# LPC408x_7x register map
File version: 0.6
CPU: CM4 r0p0, little endian, no MPU, no FPU, 3 interrupt priority bits
Registers are 32-bit, read-write, reset 0x0 unless marked. A register's access mark holds for its fields unless they carry their own. Offsets are from the block's base; [hi:lo] are bit positions; {n}, {i} and the like mark numbered series.

## GPIO
Base 0x20098000
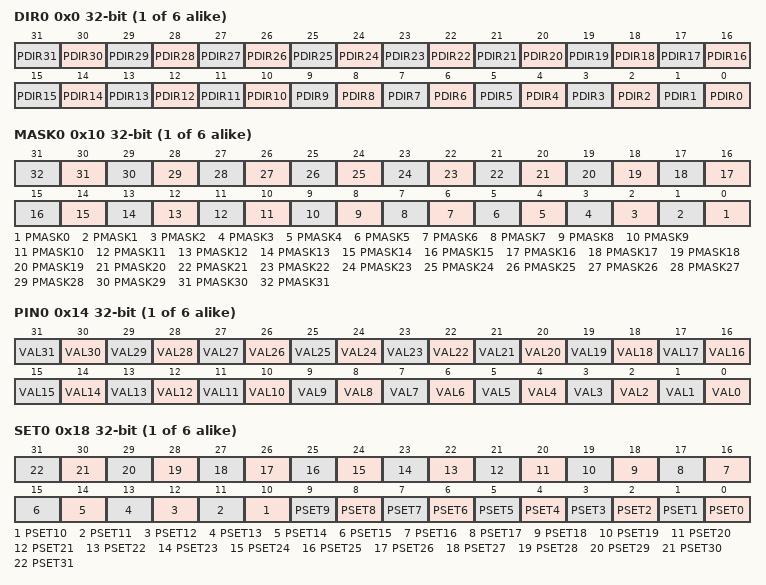
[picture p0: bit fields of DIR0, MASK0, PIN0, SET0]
{0x0+0x20*i} DIR{i} (i=0..5) — GPIO Port Direction control register.
  [n] PDIR{n} (n=0..31) — Fast GPIO Direction PORTx control bits. Bit 0 in xDIR controls pin Px[0], bit 31 in xDIR controls pin Px[31]. 0 = Controlled pin is input. 1 = Controlled pin is output.
{0x10+0x20*i} MASK{i} (i=0..5) — Mask register for Port.
  [n] PMASK{n} (n=0..31) — Fast GPIO physical pin access control. 0 = Controlled pin is affected by writes to the port's xSET, xCLR, and xPIN register(s). Current state of the pin can be read from the xPIN register. 1 = Controlled pin is not affected by writes into the port's xSET, xCLR and xPIN register(s). When the xPIN register is read, this bit will not be updated with the state of the physical pin.
{0x14+0x20*i} PIN{i} (i=0..5) — Port Pin value register using MASK.
  [n] VAL{n} (n=0..31) — Fast GPIO output value Set bits. Bit 0 in xCLR corresponds to pin Px[0], bit 31 in xCLR corresponds to pin Px[31]. 0 = Controlled pin output is set to LOW. 1 = Controlled pin output is set to HIGH.
{0x18+0x20*i} SET{i} (i=0..5) — Port Output Set register using MASK.
  [n] PSET{n} (n=0..31) — Fast GPIO output value Set bits. Bit 0 in xSET controls pin Px[0], bit 31 in xSET controls pin Px[31]. 0 = Controlled pin output is unchanged. 1 = Controlled pin output is set to HIGH.
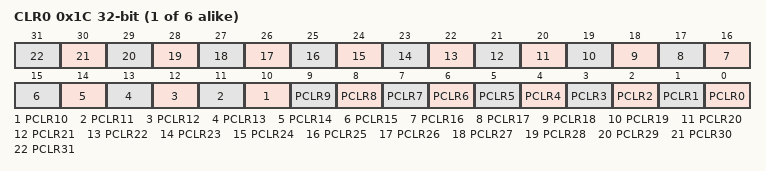
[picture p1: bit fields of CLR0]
{0x1C+0x20*i} CLR{i} (i=0..5) wo — Port Output Clear register using MASK.
  [n] PCLR{n} (n=0..31) — Fast GPIO output value Clear bits. Bit 0 in xCLR controls pin Px[0], bit 31 controls pin Px[31]. 0 = Controlled pin output is unchanged. 1 = Controlled pin output is set to LOW.

## WWDT — Windowed Watchdog Timer (WWDT)
Base 0x40000000
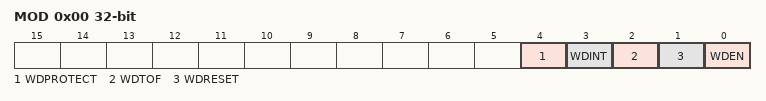
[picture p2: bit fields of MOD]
0x00 MOD — Watchdog mode register. This register determines the basic mode and status of the Watchdog Timer.
  [4] WDPROTECT — Watchdog update mode. This bit is Set Only. See Section WDPROTECT.
    0=CHANGE (The watchdog reload value (WDTC) can be changed at any time.); 1=CHANGE_W_CNT (The watchdog reload value (WDTC) can be changed only after the counter is below the value of WDWARNINT and WDWINDOW. Note: this mode is intended for use only when WDRESET =1.)
  [3] WDINT — Watchdog interrupt flag. Set when the timer reaches the value in WDWARNINT. Cleared by software. See Section WDINT.
  [2] WDTOF — Watchdog time-out flag. Set when the watchdog timer times out, by a feed error, or by events associated with WDPROTECT, cleared by software. Causes a chip reset if WDRESET = 1. See Section WDTOF.
  [1] WDRESET — Watchdog reset enable bit. This bit is Set Only. See Table 652.
    0=NORESET (A watchdog timeout will not cause a chip reset.); 1=RESET (A watchdog timeout will cause a chip reset.)
  [0] WDEN — Watchdog enable bit. This bit is Set Only. See Table 652.
    0=STOP (The watchdog timer is stopped.); 1=RUN (The watchdog timer is running.)
0x04 TC reset 0xFF — Watchdog timer constant register. The value in this register determines the time-out value.
  [23:0] Count — Watchdog time-out interval.
0x08 FEED wo reset not defined — Watchdog feed sequence register. Writing 0xAA followed by 0x55 to this register reloads the Watchdog timer with the value contained in WDTC.
  [7:0] Feed — Feed value should be 0xAA followed by 0x55.
0x0C TV ro reset 0xFF — Watchdog timer value register. This register reads out the current value of the Watchdog timer.
  [23:0] Count — Counter timer value.
0x14 WARNINT — Watchdog Warning Interrupt compare value.
  [9:0] WARNINT — Watchdog warning interrupt compare value.
0x18 WINDOW reset 0xFFFFFF — Watchdog Window compare value.
  [23:0] WINDOW — Watchdog window value.

## GPIOINT — GPIO
Base 0x40028080
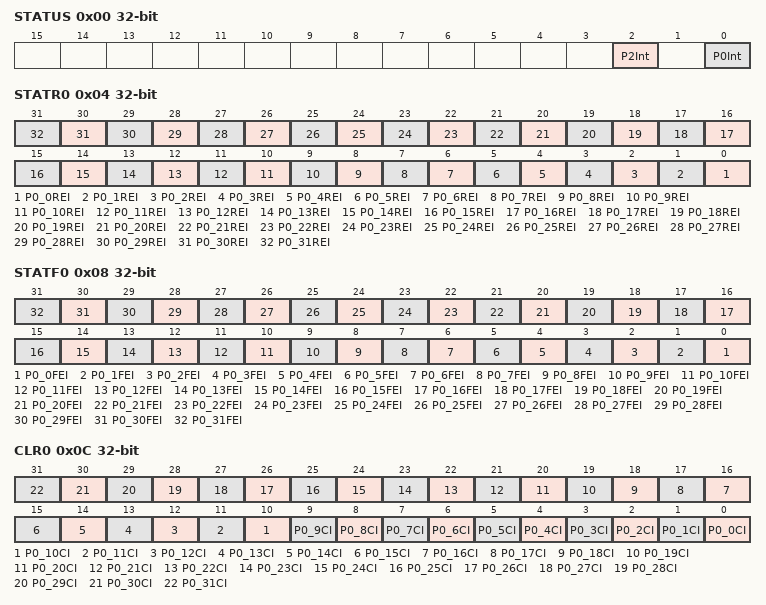
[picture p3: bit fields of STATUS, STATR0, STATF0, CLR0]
0x00 STATUS ro — GPIO overall Interrupt Status.
  [2] P2Int — Port 2 GPIO interrupt pending.
    0=NO_PENDING_INTERRUPT (No pending interrupts on Port 2.); 1=AT_LEAST_ONE_PENDING (At least one pending interrupt on Port 2.)
  [0] P0Int — Port 0 GPIO interrupt pending.
    0=NO_PENDING_INTERRUPT (No pending interrupts on Port 0.); 1=AT_LEAST_ONE_PENDING (At least one pending interrupt on Port 0.)
0x04 STATR0 ro — GPIO Interrupt Status for Rising edge for Port 0.
  [n] P0_{n}REI (n=0..31) — Status of Rising Edge Interrupt for P0[{n}]. 0 = No rising edge detected. 1 = Rising edge interrupt generated.
0x08 STATF0 ro — GPIO Interrupt Status for Falling edge for Port 0.
  [n] P0_{n}FEI (n=0..31) — Status of Falling Edge Interrupt for P0[{n}]. 0 = No falling edge detected. 1 = Falling edge interrupt generated.
0x0C CLR0 wo — GPIO Interrupt Clear.
  [n] P0_{n}CI (n=0..31) — Clear GPIO port Interrupts for P0[{n}]. 0 = No effect. 1 = Clear corresponding bits in IOnINTSTATR and IOnSTATF.
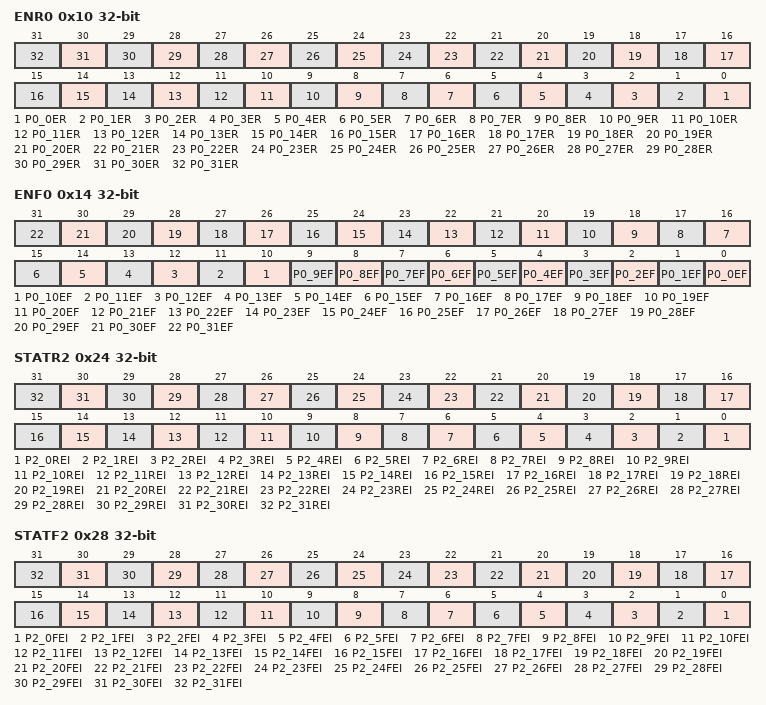
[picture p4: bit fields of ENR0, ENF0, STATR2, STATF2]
0x10 ENR0 — GPIO Interrupt Enable for Rising edge for Port 0.
  [n] P0_{n}ER (n=0..31) — Enable rising edge interrupt for P0[{n}]. 0 = Disable rising edge interrupt. 1 = Enable rising edge interrupt.
0x14 ENF0 — GPIO Interrupt Enable for Falling edge for Port 0.
  [n] P0_{n}EF (n=0..31) — Enable falling edge interrupt for P0[{n}]. 0 = Disable falling edge interrupt. 1 = Enable falling edge interrupt.
0x24 STATR2 ro — GPIO Interrupt Status for Rising edge for Port 0.
  [n] P2_{n}REI (n=0..31) — Status of Rising Edge Interrupt for P2[{n}]. 0 = No rising edge detected. 1 = Rising edge interrupt generated.
0x28 STATF2 ro — GPIO Interrupt Status for Falling edge for Port 0.
  [n] P2_{n}FEI (n=0..31) — Status of Falling Edge Interrupt for P2[{n}]. 0 = No falling edge detected. 1 = Falling edge interrupt generated.
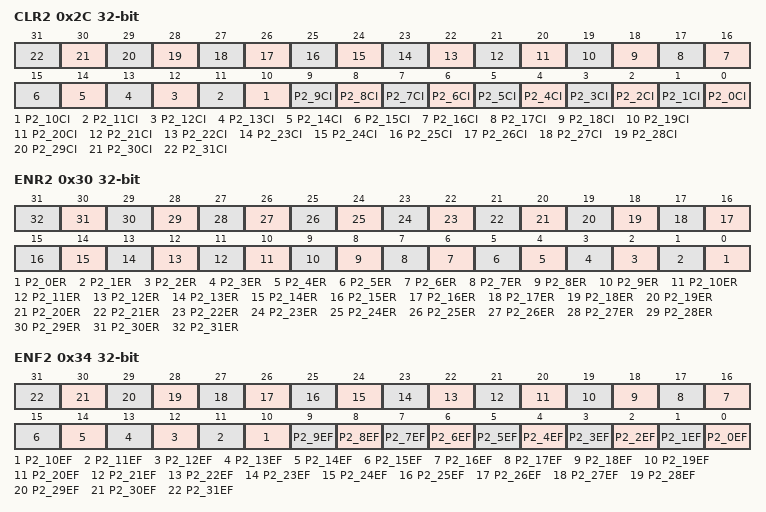
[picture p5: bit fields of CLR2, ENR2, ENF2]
0x2C CLR2 wo — GPIO Interrupt Clear.
  [n] P2_{n}CI (n=0..31) — Clear GPIO port Interrupts for P2[{n}]. 0 = No effect. 1 = Clear corresponding bits in IOnINTSTATR and IOnSTATF.
0x30 ENR2 — GPIO Interrupt Enable for Rising edge for Port 0.
  [n] P2_{n}ER (n=0..31) — Enable rising edge interrupt for P2[{n}]. 0 = Disable rising edge interrupt. 1 = Enable rising edge interrupt.
0x34 ENF2 — GPIO Interrupt Enable for Falling edge for Port 0.
  [n] P2_{n}EF (n=0..31) — Enable falling edge interrupt for P2[{n}]. 0 = Disable falling edge interrupt. 1 = Enable falling edge interrupt.
